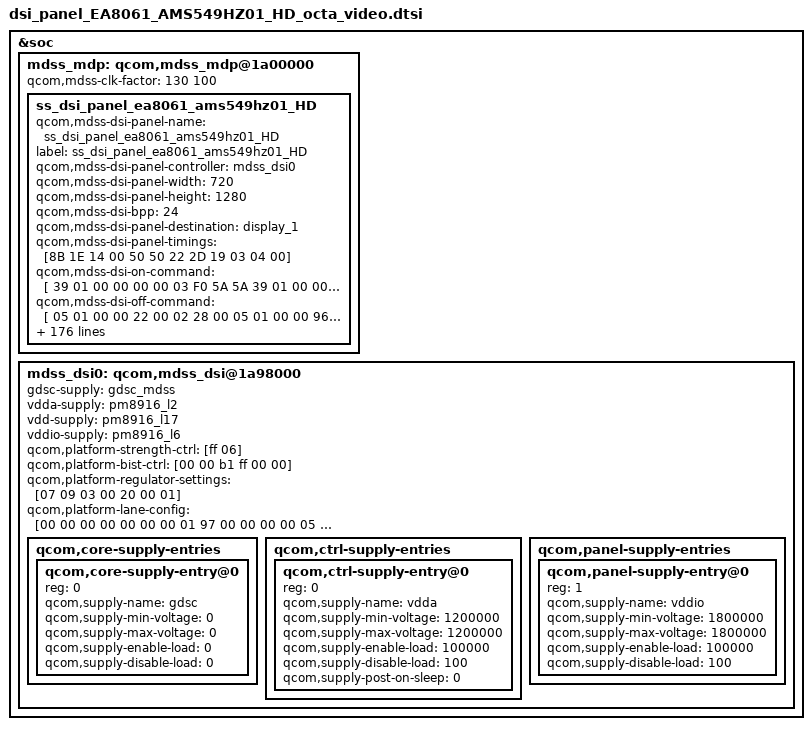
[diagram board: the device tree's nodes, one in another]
/* Copyright (c) 2013-2014, The Linux Foundation. All rights reserved.
 *
 * This program is free software; you can redistribute it and/or modify
 * it under the terms of the GNU General Public License version 2 and
 * only version 2 as published by the Free Software Foundation.
 *
 * This program is distributed in the hope that it will be useful,
 * but WITHOUT ANY WARRANTY; without even the implied warranty of
 * MERCHANTABILITY or FITNESS FOR A PARTICULAR PURPOSE.  See the
 * GNU General Public License for more details.
 */

/*---------------------------------------------------------------------------
 * This file is autogenerated file using gcdb parser. Please do not edit it.
 * Update input XML file to add a new entry or update variable in this file
 * VERSION = "1.0"
 *--------------------------------------------------------------------------- */
&mdss_mdp {
	ss_dsi_panel_ea8061_ams549hz01_HD: ss_dsi_panel_ea8061_ams549hz01_HD {
		qcom,mdss-dsi-panel-name = "ss_dsi_panel_ea8061_ams549hz01_HD";
		label = "ss_dsi_panel_ea8061_ams549hz01_HD";
		qcom,mdss-dsi-panel-controller = <&mdss_dsi0>;

		qcom,mdss-dsi-panel-width = <720>;
		qcom,mdss-dsi-panel-height = <1280>;
		qcom,mdss-dsi-bpp = <24>;
		qcom,mdss-dsi-panel-destination = "display_1";

		//qcom,mdss-dsi-panel-timings = [8B 1E 14 00 44 48 18 22 19 03 04 00];	// 488Mbps
		//qcom,mdss-dsi-panel-timings = [8B 1E 14 00 44 46 18 20 19 03 04 00];  // 481 Mbps
		qcom,mdss-dsi-panel-timings = [8B 1E 14 00 50 50 22 2D 19 03 04 00]; // New

		qcom,mdss-dsi-on-command = [
			// 4. Common Setting
			39 01 00 00 00 00 03 F0 5A 5A
			39 01 00 00 01 00 03 F7 5A 5A
			39 01 00 00 01 00 20
			/* (481 Mbps) */
			C4 51 AD 51 AD 60 95 60
			95 00 00 0B F1 00 0B F1
			00 00 08 08 08 34 64 A5
			00 00 0A 04 03 00 0C 00

			39 01 00 00 01 00 03 F7 A5 A5
			39 01 00 00 01 00 02 36 02		// Scan Direction : Reverse Scan
			39 01 00 00 01 00 05 B3 00 00 00 30	// AOR 3.7 %
			39 01 00 00 01 00 04 B4 33 07 00	// SLEW Control

			05 01 00 00 78 00 02 11 00		// sleep out &  Wait 120 ms

			// 5. Brightness Setting
			39 01 00 00 01 00 03 F7 5A 5A
			39 01 00 00 01 00 21
			CA 01 00 01 00 01 00 80			// 350 nit / 2.0 Gamma
			80 80 80 80 80 80 80 80
			80 80 80 80 80 80 80 80
			80 80 80 80 80 80 80 00
			00
			39 01 00 00 01 00 05 B3 00 00 00 30		// AOR 3.7%
			39 01 00 00 01 00 03 F7 A5 A5
			39 01 00 00 01 00 07 B2 0F B4 A0 13 00 00	// ELVSS SET
			39 01 00 00 01 00 03 F1 5A 5A
			39 01 00 00 01 00 04 D4 38 00 48		// MPS SET
			39 01 00 00 01 00 03 F1 A5 A5
			39 01 00 00 01 00 02 55 02			// 0x00 : ACL2 OFF,  0x02 : ACL 15 %

			// 6. ELVSS Temp Compensation
			39 01 00 00 01 00 02 B0 06			// Global Para (7)
			39 01 00 00 01 00 02 B2 19			// 0x19 : 25 Celsius
			39 01 00 00 01 00 03 F1 5A 5A
			39 01 00 00 01 00 02 B0 02			// Global Para (3)
			39 01 00 00 01 00 02 D4 48			// MPS Temp Offset OFF
			39 01 00 00 01 00 03 F1 A5 A5
			39 01 00 00 01 00 02 B2 0F

			// 7. ETC Condition Setting
			// 7.1 Test1 OUT (DE)
			39 01 00 00 01 00 03  F1 5A 5A
			39 01 00 00 01 00 03  FC 5A 5A
			39 01 00 00 01 00 02  B0 01
			39 01 00 00 01 00 02  D7 0A
			39 01 00 00 01 00 02  FF 0A
			39 01 00 00 01 00 03  F1 A5 A5
			39 01 00 00 01 00 03  FC A5 A5

			05 01 00 00 22 00 02 29 00
		];

		qcom,mdss-dsi-off-command = [
			05 01 00 00 22 00 02 28 00
			05 01 00 00 96 00 02 10 00
		];

		qcom,cont-splash-enabled;
		qcom,mdss-dsi-h-back-porch = <128>;
		qcom,mdss-dsi-h-front-porch = <84>;
		qcom,mdss-dsi-h-pulse-width = <96>;
		qcom,mdss-dsi-h-sync-skew = <0>;
		qcom,mdss-dsi-v-back-porch = <5>;
		qcom,mdss-dsi-v-front-porch = <13>;
		qcom,mdss-dsi-v-pulse-width = <2>;

		qcom,mdss-dsi-h-left-border = <0>;
		qcom,mdss-dsi-h-right-border = <0>;
		qcom,mdss-dsi-v-top-border = <0>;
		qcom,mdss-dsi-v-bottom-border = <0>;

		qcom,mdss-dsi-underflow-color = <0xff>;
		qcom,mdss-dsi-border-color = <0>;

		/* Dynamic FPS */
		/* qcom,mdss-dsi-pan-enable-dynamic-fps= <1>; */
		/* qcom,mdss-dsi-pan-fps-update = "dfps_immediate_porch_mode"; */

		qcom,mdss-dsi-bl-pmic-control-type = "bl_ctrl_dcs";
		qcom,mdss-dsi-bl-min-level = <1>;
		qcom,mdss-dsi-bl-max-level = <255>;
		qcom,mdss-brightness-max-level = <255>;
		qcom,mdss-dsi-panel-type = "dsi_video_mode";

		qcom,mdss-dsi-gamma-update = [
			39 01 00 00 00 00 02 F7 01
		];
		qcom,mdss-dsi-h-sync-pulse = <0>;
		qcom,mdss-dsi-bllp-eof-power-mode;
		qcom,mdss-dsi-bllp-power-mode;
		qcom,mdss-dsi-traffic-mode = "burst_mode";
		qcom,mdss-dsi-virtual-channel-id = <0>;
		qcom,mdss-dsi-lane-0-state;
		qcom,mdss-dsi-lane-1-state;
		qcom,mdss-dsi-lane-2-state;
		qcom,mdss-dsi-lane-3-state;

		qcom,mdss-dsi-t-clk-pre = <0x1C>;
		qcom,mdss-dsi-t-clk-post = <0x04>;

		qcom,mdss-dsi-stream = <0>;
		qcom,mdss-dsi-mdp-trigger = "none";
		qcom,mdss-dsi-dma-trigger = "trigger_sw";
		qcom,mdss-dsi-panel-framerate = <60>;
		qcom,mdss-dsi-on-command-state = "dsi_lp_mode";
		qcom,mdss-dsi-off-command-state = "dsi_hs_mode";
		qcom,mdss-pan-physical-width-dimension = <68>;
		qcom,mdss-pan-physical-height-dimension = <121>;
		qcom,mdss-dsi-force-clk-lane-hs = <1>;
		qcom,mdss-dsi-reset-sequence = <1 20>, <0 1>, <1 20>;

		qcom,mdss-dsi-lp11-init;
		qcom,mdss-dsi-init-delay-us = <2000>;
		qcom,mdss-power-off-delay-us = <12000>;
		samsung,mdss-power-on-reset-delay-us = <3000>;
		/*qcom,ulps-enabled*/
/*
 * ************************************************************************************************************************************
 *
 *			Below  parameters are samsung dependent thigs
 *
 * ************************************************************************************************************************************
 */
		/*samsung,dsi-lp11-init;  */
		samsung,packet_size_tx_cmds_revA = [
			37 01 00 00 00 00 02 07 00
		];

		samsung,reg_read_pos_tx_cmds_revA = [
			15 01 00 00 00 00 02 B0 00
		];
		samsung,display_on_tx_cmds_revA = [05 01 00 00 32 00 02 29 00];
		samsung,display_off_tx_cmds_revA = [05 01 00 00 32 00 02 28 00];

		samsung,level1_key_enable_tx_cmds_revA  = [39 00 00 00 00 00 03 F0 5A 5A];
		samsung,level1_key_disable_tx_cmds_revA = [39 00 00 00 00 00 03 F0 A5 A5];
		samsung,level2_key_enable_tx_cmds_revA = [
						39 00 00 00 00 00 03 F0 5A 5A
						39 00 00 00 00 00 03 F1 5A 5A
						39 01 00 00 00 00 03 FC 5A 5A
		];
		samsung,level2_key_disable_tx_cmds_revA = [
						39 00 00 00 00 00 03 F0 5A 5A
						39 00 00 00 00 00 03 F1 A5 A5
						39 01 00 00 00 00 03 FC A5 A5
		];

		samsung,manufacture_read_pre_tx_cmds_revA = [
						05 01 00 00 78 00 02 11 00		// sleep out
						39 01 00 00 00 00 03 FD DA 00		// mtp read
						];

		/*
		 * ************************************************************************************************************************
		 *	 06 01 00 00 00 00 01 c8 07 21
		 *	READ 0xC8 SIZE 0x07 OFFSET 0x21
		 * ************************************************************************************************************************
		 */
		samsung,panel-mtp-read-cmds = [ 39 01 00 00 00 00 03 FD DA 00];

		//=================================
		// REV. A
		//=================================
		samsung,smart_dimming_mtp_rx_cmds_revA = [ 06 01 00 00 00 00 01 FE 20 00];
		samsung,manufacture_id0_rx_cmds_revA   = [ 06 01 00 00 00 00 01 DA 01 00];
		samsung,manufacture_id1_rx_cmds_revA   = [ 06 01 00 00 00 00 01 DB 01 00];
		samsung,manufacture_id2_rx_cmds_revA   = [ 06 01 00 00 00 00 01 DC 01 00];
		samsung,manufacture_date_rx_cmds_revA  = [ 06 01 00 00 00 00 01 FE 02 32];	// read B6 24~25th, 23=0x17
		samsung,ddi_id_rx_cmds_revA            = [ 06 01 00 00 00 00 01 d6 05 00];	// read D6 1~5th
		samsung,mtp_read_sysfs_rx_cmds_revA    = [ 06 01 00 00 00 00 01 01 01 01];
		samsung,elvss_rx_cmds_revA             = [ 06 01 00 00 00 00 01 FE 01 11];	// read C6 21th, 20=0x14
		samsung,ldi_debug0_rx_cmds_revA        = [ 06 01 00 00 00 00 01 0A 01 00];
		samsung,ldi_debug1_rx_cmds_revA        = [ 06 01 00 00 00 00 01 0E 01 00];
		samsung,ldi_debug2_rx_cmds_revA        = [ 06 01 00 00 00 00 01 EA 08 00];
		samsung,hbm_rx_cmds_revA               = [ 06 01 00 00 00 00 01 FE 15 00];	// read DB 1~21th, 00=0x00
		samsung,hbm2_rx_cmds_revA              = [ 06 01 00 00 00 00 01 FE 01 21];	// read DB 34th, 33=0x21

		//=================================
		// REV. E
		//=================================
		samsung,smart_dimming_mtp_rx_cmds_revE = [ 06 01 00 00 00 00 01 FE 20 00];
		samsung,manufacture_id0_rx_cmds_revE   = [ 06 01 00 00 00 00 01 DA 01 00];
		samsung,manufacture_id1_rx_cmds_revE   = [ 06 01 00 00 00 00 01 DB 01 00];
		samsung,manufacture_id2_rx_cmds_revE   = [ 06 01 00 00 00 00 01 DC 01 00];
		samsung,manufacture_date_rx_cmds_revE  = [ 06 01 00 00 00 00 01 FE 02 32];	// read B6 24~25th, 23=0x17
		samsung,ddi_id_rx_cmds_revE            = [ 06 01 00 00 00 00 01 d6 02 32];	// read D6 1~5th
		samsung,mtp_read_sysfs_rx_cmds_revE    = [ 06 01 00 00 00 00 01 01 01 01];
		samsung,elvss_rx_cmds_revE             = [ 06 01 00 00 00 00 01 FE 01 11];	// read C6 21th, 20=0x14
		samsung,ldi_debug0_rx_cmds_revE        = [ 06 01 00 00 00 00 01 0A 01 00];
		samsung,ldi_debug1_rx_cmds_revE        = [ 06 01 00 00 00 00 01 0E 01 00];
		samsung,ldi_debug2_rx_cmds_revE        = [ 06 01 00 00 00 00 01 EA 08 00];
		samsung,hbm_rx_cmds_revE               = [ 06 01 00 00 00 00 01 FE 15 00];	// read DB 1~21th, 00=0x00
		samsung,hbm2_rx_cmds_revE              = [ 06 01 00 00 00 00 01 FE 01 21];	// read DB 34th, 33=0x21

		/*
		 * ************************************************************************************************************************
		 *	 COMMON CMD LIST
		 * ************************************************************************************************************************
		 */
		samsung,elvss_lowtemp_tx_cmds_revA  = [	29 01 00 00 00 00 02 B2 00 ];	/* Low Temperature Command */
		samsung,elvss_lowtemp2_tx_cmds_revA = [	29 01 00 00 00 00 02 B2 00 ];	/* Low Temperature Command: default */

		//========================================
		// Gamma and HBM (REV. A)
		//========================================
		samsung,gamma_tx_cmds_revA = [
			39 01 00 00 00 00 02 B0 06
			39 01 00 00 00 00 02 B2 25
			39 01 00 00 00 00 02 B0 02
			39 01 00 00 00 00 02 D4 48
			39 01 00 00 00 00 03 F7 5A 5A
			39 01 00 00 00 00 21 CA 01
			00 01 00 01 00 80 80 80
			80 80 80 80 80 80 80 80
			80 80 80 80 80 80 80 80
			80 80 80 80 80 00 00
			39 01 00 00 00 00 03 F7 A5 A5
		];

		samsung,hbm_gamma_tx_cmds_revA = [
			39 01 00 00 00 00 03 F7 5A 5A
			39 01 00 00 00 00 21 CA 01
			00 01 00 01 00 80 80 80
			80 80 80 80 80 80 80 80
			80 80 80 80 80 80 80 80
			80 80 80 80 80 00 00
			39 01 00 00 00 00 03 F7 A5 A5
		];

		samsung,hbm_etc_tx_cmds_revA = [
			39 00 00 00 00 00 05 B3 00 06 00 06
			39 00 00 00 00 00 08 B2 0F B4 A0 13 00 00 00
			39 00 00 00 00 00 04 B4 35 0A 00
			39 00 00 00 00 00 1F D4 38 00 48
			00 00 00 00 00 00 00
			00 00 00 60 66 C6 0C
			00 00 00 00 00 00 00
			00 00 00 00 00 00
			39 00 00 00 00 00 02 55 02
		];

		//========================================
		// Gamma and HBM (REV. E)
		//========================================
		samsung,gamma_tx_cmds_revE = [
			39 01 00 00 00 00 02 B0 06
			39 01 00 00 00 00 02 B2 19                      // TSET : 0x19 : 25 Celsius
			39 00 00 00 00 00 03 F1 5A 5A
			39 01 00 00 00 00 02 B0 02                      // Global Para 3rd
			39 01 00 00 00 00 02 D4 48                      // MPS Setting : MPS Temp offset off
			39 01 00 00 00 00 02 B0 11                      // Global Para 18 th
			39 01 00 00 00 00 02 D4 0C                      /* elvss set */
			39 00 00 00 00 00 03 F1 A5 A5
			39 01 00 00 00 00 03 F7 5A 5A                   /* Gamma, LTPS(AID) update */
			39 01 00 00 00 00 21 CA 01                      /* Brightness Condition Set - Gamma 2.0 Setting*/
			00 01 00 01 00 80 80 80
			80 80 80 80 80 80 80 80
			80 80 80 80 80 80 80 80
			80 80 80 80 80 00 00
			39 01 00 00 00 00 03 F7 A5 A5                   /* Gamma, LTPS(AID) update */
		];

		samsung,hbm_gamma_tx_cmds_revE = [
			39 01 00 00 00 00 03 F7 5A 5A
			39 01 00 00 00 00 21 CA 01			/* Brightness Condition Set - Gamma 2.0 Setting*/
			00 01 00 01 00 80 80 80
			80 80 80 80 80 80 80 80
			80 80 80 80 80 80 80 80
			80 80 80 80 80 00 00
			39 01 00 00 00 00 03 F7 A5 A5
		];

		samsung,hbm_etc_tx_cmds_revE = [
			39 00 00 00 00 00 05 B3 00 00 00 30             // AOR 3.7 %
			39 00 00 00 00 00 07 B2 0F B4 A0 13 00 00       // ELVSS SET
			39 00 00 00 00 00 03 F1 5A 5A
			39 00 00 00 00 00 1F D4 38 00 48
			00 00 00 00 00 00 00
			00 00 00 60 66 C6 0C
			00 00 00 00 00 00 00                            // DB 34th Para
			00 00 00 00 00 00
			39 00 00 00 00 00 03 F1 A5 A5
			39 00 00 00 00 00 02 55 02                      //0x02 :  ACL 15 %
		];

		//========================================
		// AID command list and mappings (REV. A)
		//========================================
		samsung,aid_tx_cmds_revA = [
			39 01 00 00 00 00 05	B3 00 00 04 EB	/* 0 samsung_brightness_aor_96p37 */
			39 01 00 00 00 00 05	B3 00 00 04 DE	/* 1 samsung_brightness_aor_95p29 */
			39 01 00 00 00 00 05	B3 00 00 04 D6	/* 2 samsung_brightness_aor_94p29 */
			39 01 00 00 00 00 05	B3 00 00 04 CB	/* 3 samsung_brightness_aor_93p75 */
			39 01 00 00 00 00 05	B3 00 00 04 BE	/* 4 samsung_brightness_aor_92p82 */
			39 01 00 00 00 00 05	B3 00 00 04 B7	/* 5 samsung_brightness_aor_91p82 */
			39 01 00 00 00 00 05	B3 00 00 04 AC	/* 6 samsung_brightness_aor_90p74 */
			39 01 00 00 00 00 05	B3 00 00 04 9F	/* 7 samsung_brightness_aor_90p28 */
			39 01 00 00 00 00 05	B3 00 00 04 98	/* 8 samsung_brightness_aor_89p20 */
			39 01 00 00 00 00 05	B3 00 00 04 8C	/* 9 samsung_brightness_aor_88p12 */
			39 01 00 00 00 00 05	B3 00 00 04 88	/* 10 samsung_brightness_aor_87p11 */
			39 01 00 00 00 00 05	B3 00 00 04 78	/* 11 samsung_brightness_aor_86p57 */
			39 01 00 00 00 00 05	B3 00 00 04 6D	/* 12 samsung_brightness_aor_85p57 */
			39 01 00 00 00 00 05	B3 00 00 04 57	/* 13 samsung_brightness_aor_83p41 */
			39 01 00 00 00 00 05	B3 00 00 04 4C	/* 14 samsung_brightness_aor_82p87 */
			39 01 00 00 00 00 05	B3 00 00 04 3D	/* 15 samsung_brightness_aor_81p87 */
			39 01 00 00 00 00 05	B3 00 00 04 30	/* 16 samsung_brightness_aor_81p40 */
			39 01 00 00 00 00 05	B3 00 00 04 1B	/* 17 samsung_brightness_aor_79p32 */
			39 01 00 00 00 00 05	B3 00 00 04 0C	/* 18 samsung_brightness_aor_78p24 */
			39 01 00 00 00 00 05	B3 00 00 03 F2	/* 19 samsung_brightness_aor_76p24 */
			39 01 00 00 00 00 05	B3 00 00 03 D9	/* 20 samsung_brightness_aor_74p69 */
			39 01 00 00 00 00 05	B3 00 00 03 D0	/* 21 samsung_brightness_aor_74p23 */
			39 01 00 00 00 00 05	B3 00 00 03 B8	/* 22 samsung_brightness_aor_72p07 */
			39 01 00 00 00 00 05	B3 00 00 03 A0	/* 23 samsung_brightness_aor_70p68 */
			39 01 00 00 00 00 05	B3 00 00 03 80	/* 24 samsung_brightness_aor_68p06 */
			39 01 00 00 00 00 05	B3 00 00 03 69	/* 25 samsung_brightness_aor_65p74 */
			39 01 00 00 00 00 05	B3 00 00 03 51	/* 26 samsung_brightness_aor_64p35 */
			39 01 00 00 00 00 05	B3 00 00 03 2E	/* 27 samsung_brightness_aor_61p11 */
			39 01 00 00 00 00 05	B3 00 00 03 0C	/* 28 samsung_brightness_aor_58p49 */
			39 01 00 00 00 00 05	B3 00 00 02 E9	/* 29 samsung_brightness_aor_55p71 */
			39 01 00 00 00 00 05	B3 00 00 02 C5	/* 30 samsung_brightness_aor_52p47 */
			39 01 00 00 00 00 05	B3 00 00 02 A1	/* 31 samsung_brightness_aor_49p69 */
			39 01 00 00 00 00 05	B3 00 00 02 70	/* 32 samsung_brightness_aor_45p99 */
			39 01 00 00 00 00 05	B3 00 00 02 41	/* 33 samsung_brightness_aor_42p52 */
			39 01 00 00 00 00 05	B3 00 00 02 10	/* 34 samsung_brightness_aor_39p89 */
			39 01 00 00 00 00 05	B3 00 00 01 DC	/* 35 samsung_brightness_aor_39p89 */
			39 01 00 00 00 00 05	B3 00 00 01 DC	/* 36 samsung_brightness_aor_33p95 */
			39 01 00 00 00 00 05	B3 00 00 01 A0	/* 37 samsung_brightness_aor_29p78 */
			39 01 00 00 00 00 05	B3 00 00 01 60	/* 38 samsung_brightness_aor_23p77 */
			39 01 00 00 00 00 05	B3 00 00 01 1C	/* 39 samsung_brightness_aor_18p83 */
			39 01 00 00 00 00 05	B3 00 00 00 D7	/* 40 samsung_brightness_aor_12p89 */
			39 01 00 00 00 00 05	B3 00 00 00 87	/* 41 samsung_brightness_aor_7p56 */
			39 01 00 00 00 00 05	B3 00 00 00 30	/* 42 samsung_brightness_aor_0p46 */
		];

		samsung,aid_map_table_revA = <
			5	0		6	1		7	2		8	3		9	4
			10	5		11	6		12	7		13	8		14	9
			15	10		16	11		17	12		19	13		20	14
			21	15		22	16		24	17		25	18		27	19	// 20
			29	20		30	21		32	22		34	23		37	24
			39	25		41	26		44	27		47	28		50	29
			53	30		56	31		60	32		64	33		68	34
			72	35		77	35		82	35		87	35		93	35	// 40
			98	35		105	35		111	35		119	35		126	35
			134	35		143	35		152	35		162	35		172	36
			183	37		195	38		207	39		220	40		234	41
			249	42		265	42		282	42		300	42		316	42	// 60
			333	42		350	42
		>;

		//=======================================
		// AID command list and mappings (REV. E)
		//=======================================
		samsung,aid_tx_cmds_revE = [
			39 01 00 00 00 00 05	B3 00 00 04 EB	/* 0 samsung_brightness_aor_96p37 */
			39 01 00 00 00 00 05	B3 00 00 04 DE	/* 1 samsung_brightness_aor_95p29 */
			39 01 00 00 00 00 05	B3 00 00 04 D6	/* 2 samsung_brightness_aor_94p29 */
			39 01 00 00 00 00 05	B3 00 00 04 CB	/* 3 samsung_brightness_aor_93p75 */
			39 01 00 00 00 00 05	B3 00 00 04 BE	/* 4 samsung_brightness_aor_92p82 */
			39 01 00 00 00 00 05	B3 00 00 04 B7	/* 5 samsung_brightness_aor_91p82 */
			39 01 00 00 00 00 05	B3 00 00 04 AC	/* 6 samsung_brightness_aor_90p74 */
			39 01 00 00 00 00 05	B3 00 00 04 9F	/* 7 samsung_brightness_aor_90p28 */
			39 01 00 00 00 00 05	B3 00 00 04 98	/* 8 samsung_brightness_aor_89p20 */
			39 01 00 00 00 00 05	B3 00 00 04 8C	/* 9 samsung_brightness_aor_88p12 */
			39 01 00 00 00 00 05	B3 00 00 04 88	/* 10 samsung_brightness_aor_87p11 */
			39 01 00 00 00 00 05	B3 00 00 04 78	/* 11 samsung_brightness_aor_86p57 */
			39 01 00 00 00 00 05	B3 00 00 04 6D	/* 12 samsung_brightness_aor_85p57 */
			39 01 00 00 00 00 05	B3 00 00 04 57	/* 13 samsung_brightness_aor_83p41 */
			39 01 00 00 00 00 05	B3 00 00 04 4C	/* 14 samsung_brightness_aor_82p87 */
			39 01 00 00 00 00 05	B3 00 00 04 3D	/* 15 samsung_brightness_aor_81p87 */
			39 01 00 00 00 00 05	B3 00 00 04 30	/* 16 samsung_brightness_aor_81p40 */
			39 01 00 00 00 00 05	B3 00 00 04 1B	/* 17 samsung_brightness_aor_79p32 */
			39 01 00 00 00 00 05	B3 00 00 04 0C	/* 18 samsung_brightness_aor_78p24 */
			39 01 00 00 00 00 05	B3 00 00 03 F2	/* 19 samsung_brightness_aor_76p24 */
			39 01 00 00 00 00 05	B3 00 00 03 D9	/* 20 samsung_brightness_aor_74p69 */
			39 01 00 00 00 00 05	B3 00 00 03 D0	/* 21 samsung_brightness_aor_74p23 */
			39 01 00 00 00 00 05	B3 00 00 03 B8	/* 22 samsung_brightness_aor_72p07 */
			39 01 00 00 00 00 05	B3 00 00 03 A0	/* 23 samsung_brightness_aor_70p68 */
			39 01 00 00 00 00 05	B3 00 00 03 80	/* 24 samsung_brightness_aor_68p06 */
			39 01 00 00 00 00 05	B3 00 00 03 69	/* 25 samsung_brightness_aor_65p74 */
			39 01 00 00 00 00 05	B3 00 00 03 51	/* 26 samsung_brightness_aor_64p35 */
			39 01 00 00 00 00 05	B3 00 00 03 2E	/* 27 samsung_brightness_aor_61p11 */
			39 01 00 00 00 00 05	B3 00 00 03 0C	/* 28 samsung_brightness_aor_58p49 */
			39 01 00 00 00 00 05	B3 00 00 02 E9	/* 29 samsung_brightness_aor_55p71 */
			39 01 00 00 00 00 05	B3 00 00 02 C5	/* 30 samsung_brightness_aor_52p47 */
			39 01 00 00 00 00 05	B3 00 00 02 A1	/* 31 samsung_brightness_aor_49p69 */
			39 01 00 00 00 00 05	B3 00 00 02 70	/* 32 samsung_brightness_aor_45p99 */
			39 01 00 00 00 00 05	B3 00 00 02 41	/* 33 samsung_brightness_aor_42p52 */
			39 01 00 00 00 00 05	B3 00 00 02 10	/* 34 samsung_brightness_aor_39p89 */
			39 01 00 00 00 00 05	B3 00 00 01 DC	/* 35 samsung_brightness_aor_39p89 */
			39 01 00 00 00 00 05	B3 00 00 01 DC	/* 36 samsung_brightness_aor_33p95 */
			39 01 00 00 00 00 05	B3 00 00 01 A0	/* 37 samsung_brightness_aor_29p78 */
			39 01 00 00 00 00 05	B3 00 00 01 60	/* 38 samsung_brightness_aor_23p77 */
			39 01 00 00 00 00 05	B3 00 00 01 1C	/* 39 samsung_brightness_aor_18p83 */
			39 01 00 00 00 00 05	B3 00 00 00 D7	/* 40 samsung_brightness_aor_12p89 */
			39 01 00 00 00 00 05	B3 00 00 00 87	/* 41 samsung_brightness_aor_7p56 */
			39 01 00 00 00 00 05	B3 00 00 00 30	/* 42 samsung_brightness_aor_0p46 */
		];

		samsung,aid_map_table_revE = <
			5	0		6	1		7	2		8	3		9	4
			10	5		11	6		12	7		13	8		14	9
			15	10		16	11		17	12		19	13		20	14
			21	15		22	16		24	17		25	18		27	19
			29	20		30	21		32	22		34	23		37	24
			39	25		41	26		44	27		47	28		50	29
			53	30		56	31		60	32		64	33		68	34
			72	35		77	35		82	35		87	35		93	35
			98	35		105	35		111	35		119	35		126	35
			134	35		143	35		152	35		162	35		172	36
			183	37		195	38		207	39		220	40		234	41
			249	42		265	42		282	42		300	42		316	42
			333	42		350	42
		>;

		//========================================
		// ACL command list and mappings (REV. A)
		//========================================
		samsung,samsung_change_acl_by_brightness;
		samsung,acl_on_tx_cmds_revA  = [ 39 01 00 00 00 00 02 55 02 ];
		samsung,acl_off_tx_cmds_revA = [ 39 01 00 00 72 00 02 55 00 ];

		samsung,acl_percent_tx_cmds_revA = [
			39 00 00 00 00 00 02 55 00	// 0x00 : ACL OFF
			39 00 00 00 00 00 02 55 01
			39 00 00 00 00 00 02 55 02	// 0x02 : ACL 15 %
			39 00 00 00 00 00 02 55 03
		];

		samsung,acl_map_table_revA =  <
			5    2	6    2	7    2	8    2	9    2
			10   2	11   2	12   2	13   2	14   2
			15   2	16   2	17   2	19   2	20   2
			21   2	22   2	24   2	25   2	27   2
			29   2	30   2	32   2	34   2	37   2
			39   2	41   2	44   2	47   2	50   2
			53   2	56   2	60   2	64   2	68   2
			72   2	77   2	82   2	87   2	93   2
			98   2	105  2	111  2	119  2	126  2
			134  2	143  2	152  2	162  2	172  2
			183  2	195  2	207  2	220  2	234  2
			249  2	265  2	282  2	300  2	316  2
			333  2	350  2
		>;

		//======================================
		// ACL command list and mappings (REV.E)
		//======================================
		samsung,acl_on_tx_cmds_revE  = [ 39 01 00 00 00 00 02 55 02 ];
		samsung,acl_off_tx_cmds_revE = [ 39 01 00 00 72 00 02 55 00 ];

		samsung,acl_percent_tx_cmds_revE = [
			39 00 00 00 00 00 02 55 00 /* 0 */
			39 00 00 00 00 00 02 55 01 /* 1 */
			39 00 00 00 00 00 02 55 02 /* 2 */
			39 00 00 00 00 00 02 55 03 /* 3 */
		];

		samsung,acl_map_table_revE =  <
			5    2	6    2	7    2	8    2	9    2
			10   2	11   2	12   2	13   2	14   2
			15   2	16   2	17   2	19   2	20   2
			21   2	22   2	24   2	25   2	27   2
			29   2	30   2	32   2	34   2	37   2
			39   2	41   2	44   2	47   2	50   2
			53   2	56   2	60   2	64   2	68   2
			72   2	77   2	82   2	87   2	93   2
			98   2	105  2	111  2	119  2	126  2
			134  2	143  2	152  2	162  2	172  2
			183  2	195  2	207  2	220  2	234  2
			249  2	265  2	282  2	300  2	316  2
			333  2	350  2
		>;
		/*
		 * ************************************************************************************************************************
		 * ELVSS(ACL Off) command list and mappings
		 * ************************************************************************************************************************
		 */
		samsung,elvss_tx_cmds_revA = [
			39 01 00 00 00 00 02 b2 0F /* 0    5 nit */
			39 01 00 00 00 00 02 b2 0F /* 1    6 nit */
			39 01 00 00 00 00 02 b2 0F /* 2    7 nit */
			39 01 00 00 00 00 02 b2 0F /* 3    8 nit */
			39 01 00 00 00 00 02 b2 0F /* 4    9 nit */
			39 01 00 00 00 00 02 b2 0F /* 5    10 nit */
			39 01 00 00 00 00 02 b2 0F /* 6    11 nit */
			39 01 00 00 00 00 02 b2 0F /* 7    12 nit */
			39 01 00 00 00 00 02 b2 0F /* 8    13 nit */
			39 01 00 00 00 00 02 b2 0F /* 9    14 nit */
			39 01 00 00 00 00 02 b2 0F /* 10   15 nit */
			39 01 00 00 00 00 02 b2 0F /* 11   16 nit */
			39 01 00 00 00 00 02 b2 0F /* 12   17 nit */
			39 01 00 00 00 00 02 b2 0F /* 13   19 nit */
			39 01 00 00 00 00 02 b2 0F /* 14   20 nit */
			39 01 00 00 00 00 02 b2 0F /* 15   21 nit */
			39 01 00 00 00 00 02 b2 11 /* 16   22 nit */
			39 01 00 00 00 00 02 b2 15 /* 17   24 nit */
			39 01 00 00 00 00 02 b2 18 /* 18   25 nit */
			39 01 00 00 00 00 02 b2 1B /* 19   27 nit */
			39 01 00 00 00 00 02 b2 19 /* 20   29 nit */
			39 01 00 00 00 00 02 b2 1C /* 21   30 ~ 105 nit */
			39 01 00 00 00 00 02 b2 1C /* 22   111 nit */
			39 01 00 00 00 00 02 b2 1B /* 23   119 nit */
			39 01 00 00 00 00 02 b2 1B /* 24   126 nit */
			39 01 00 00 00 00 02 b2 1A /* 25   134 nit */
			39 01 00 00 00 00 02 b2 19 /* 26   143 nit */
			39 01 00 00 00 00 02 b2 18 /* 27   152 nit */
			39 01 00 00 00 00 02 b2 17 /* 28   162 nit */
			39 01 00 00 00 00 02 b2 17 /* 29   172 nit */
			39 01 00 00 00 00 02 b2 17 /* 30   183 nit */
			39 01 00 00 00 00 02 b2 16 /* 31   195 nit */
			39 01 00 00 00 00 02 b2 15 /* 32   207 nit */
			39 01 00 00 00 00 02 b2 15 /* 33   220 nit */
			39 01 00 00 00 00 02 b2 15 /* 34   234 nit */
			39 01 00 00 00 00 02 b2 14 /* 35   249 nit */
			39 01 00 00 00 00 02 b2 14 /* 36   265 nit */
			39 01 00 00 00 00 02 b2 13 /* 37   282 nit */
			39 01 00 00 00 00 02 b2 12 /* 38   300 nit */
			39 01 00 00 00 00 02 b2 11 /* 39   316 nit */
			39 01 00 00 00 00 02 b2 10 /* 40   333 nit */
			39 01 00 00 00 00 02 b2 0F /* 41   350 nit */
		];

		samsung,elvss_tx_cmds_revE = [
			39 01 00 00 00 00 02 b2 0F /* 0    5 nit */
			39 01 00 00 00 00 02 b2 0F /* 1    6 nit */
			39 01 00 00 00 00 02 b2 0F /* 2    7 nit */
			39 01 00 00 00 00 02 b2 0F /* 3    8 nit */
			39 01 00 00 00 00 02 b2 0F /* 4    9 nit */
			39 01 00 00 00 00 02 b2 0F /* 5    10 nit */
			39 01 00 00 00 00 02 b2 0F /* 6    11 nit */
			39 01 00 00 00 00 02 b2 0F /* 7    12 nit */
			39 01 00 00 00 00 02 b2 0F /* 8    13 nit */
			39 01 00 00 00 00 02 b2 0F /* 9    14 nit */
			39 01 00 00 00 00 02 b2 0F /* 10   15 nit */
			39 01 00 00 00 00 02 b2 0F /* 11   16 nit */
			39 01 00 00 00 00 02 b2 0F /* 12   17 nit */
			39 01 00 00 00 00 02 b2 0F /* 13   19 nit */
			39 01 00 00 00 00 02 b2 0F /* 14   20 nit */
			39 01 00 00 00 00 02 b2 0F /* 15   21 nit */
			39 01 00 00 00 00 02 b2 11 /* 16   22 nit */
			39 01 00 00 00 00 02 b2 15 /* 17   24 nit */
			39 01 00 00 00 00 02 b2 18 /* 18   25 nit */
			39 01 00 00 00 00 02 b2 1B /* 19   27 nit */
			39 01 00 00 00 00 02 b2 19 /* 20   29 nit */
			39 01 00 00 00 00 02 b2 1C /* 21   30 ~ 105 nit */
			39 01 00 00 00 00 02 b2 1C /* 22   111 nit */
			39 01 00 00 00 00 02 b2 1B /* 23   119 nit */
			39 01 00 00 00 00 02 b2 1B /* 24   126 nit */
			39 01 00 00 00 00 02 b2 1A /* 25   134 nit */
			39 01 00 00 00 00 02 b2 19 /* 26   143 nit */
			39 01 00 00 00 00 02 b2 18 /* 27   152 nit */
			39 01 00 00 00 00 02 b2 17 /* 28   162 nit */
			39 01 00 00 00 00 02 b2 17 /* 29   172 nit */
			39 01 00 00 00 00 02 b2 17 /* 30   183 nit */
			39 01 00 00 00 00 02 b2 16 /* 31   195 nit */
			39 01 00 00 00 00 02 b2 15 /* 32   207 nit */
			39 01 00 00 00 00 02 b2 15 /* 33   220 nit */
			39 01 00 00 00 00 02 b2 15 /* 34   234 nit */
			39 01 00 00 00 00 02 b2 14 /* 35   249 nit */
			39 01 00 00 00 00 02 b2 14 /* 36   265 nit */
			39 01 00 00 00 00 02 b2 13 /* 37   282 nit */
			39 01 00 00 00 00 02 b2 12 /* 38   300 nit */
			39 01 00 00 00 00 02 b2 11 /* 39   316 nit */
			39 01 00 00 00 00 02 b2 10 /* 40   333 nit */
			39 01 00 00 00 00 02 b2 0F /* 41   350 nit */
		];

		/*
		 * ************************************************************************************************************************
		 * SMART ACL(ACL On) ELVSS command list and mappings
		 * ************************************************************************************************************************
		 */

		samsung,smart_acl_elvss_tx_cmds_revA = [
			39 01 00 00 00 00 02 b2 0F /* 0    5 nit */
			39 01 00 00 00 00 02 b2 0F /* 1    6 nit */
			39 01 00 00 00 00 02 b2 0F /* 2    7 nit */
			39 01 00 00 00 00 02 b2 0F /* 3    8 nit */
			39 01 00 00 00 00 02 b2 0F /* 4    9 nit */
			39 01 00 00 00 00 02 b2 0F /* 5    10 nit */
			39 01 00 00 00 00 02 b2 0F /* 6    11 nit */
			39 01 00 00 00 00 02 b2 0F /* 7    12 nit */
			39 01 00 00 00 00 02 b2 0F /* 8    13 nit */
			39 01 00 00 00 00 02 b2 0F /* 9    14 nit */
			39 01 00 00 00 00 02 b2 0F /* 10   15 nit */
			39 01 00 00 00 00 02 b2 0F /* 11   16 nit */
			39 01 00 00 00 00 02 b2 0F /* 12   17 nit */
			39 01 00 00 00 00 02 b2 0F /* 13   19 nit */
			39 01 00 00 00 00 02 b2 0F /* 14   20 nit */
			39 01 00 00 00 00 02 b2 0F /* 15   21 nit */
			39 01 00 00 00 00 02 b2 11 /* 16   22 nit */
			39 01 00 00 00 00 02 b2 15 /* 17   24 nit */
			39 01 00 00 00 00 02 b2 18 /* 18   25 nit */
			39 01 00 00 00 00 02 b2 1B /* 19   27 nit */
			39 01 00 00 00 00 02 b2 19 /* 20   29 nit */
			39 01 00 00 00 00 02 b2 1C /* 21   30 ~ 105 nit */
			39 01 00 00 00 00 02 b2 1C /* 22   111 nit */
			39 01 00 00 00 00 02 b2 1B /* 23   119 nit */
			39 01 00 00 00 00 02 b2 1B /* 24   126 nit */
			39 01 00 00 00 00 02 b2 1A /* 25   134 nit */
			39 01 00 00 00 00 02 b2 19 /* 26   143 nit */
			39 01 00 00 00 00 02 b2 18 /* 27   152 nit */
			39 01 00 00 00 00 02 b2 17 /* 28   162 nit */
			39 01 00 00 00 00 02 b2 17 /* 29   172 nit */
			39 01 00 00 00 00 02 b2 17 /* 30   183 nit */
			39 01 00 00 00 00 02 b2 16 /* 31   195 nit */
			39 01 00 00 00 00 02 b2 15 /* 32   207 nit */
			39 01 00 00 00 00 02 b2 15 /* 33   220 nit */
			39 01 00 00 00 00 02 b2 15 /* 34   234 nit */
			39 01 00 00 00 00 02 b2 14 /* 35   249 nit */
			39 01 00 00 00 00 02 b2 14 /* 36   265 nit */
			39 01 00 00 00 00 02 b2 13 /* 37   282 nit */
			39 01 00 00 00 00 02 b2 12 /* 38   300 nit */
			39 01 00 00 00 00 02 b2 11 /* 39   316 nit */
			39 01 00 00 00 00 02 b2 10 /* 40   333 nit */
			39 01 00 00 00 00 02 b2 0F /* 41   350 nit */
		];
		samsung,smart_acl_elvss_tx_cmds_revE = [
			39 01 00 00 00 00 02 b2 0F /* 0    5 nit */
			39 01 00 00 00 00 02 b2 0F /* 1    6 nit */
			39 01 00 00 00 00 02 b2 0F /* 2    7 nit */
			39 01 00 00 00 00 02 b2 0F /* 3    8 nit */
			39 01 00 00 00 00 02 b2 0F /* 4    9 nit */
			39 01 00 00 00 00 02 b2 0F /* 5    10 nit */
			39 01 00 00 00 00 02 b2 0F /* 6    11 nit */
			39 01 00 00 00 00 02 b2 0F /* 7    12 nit */
			39 01 00 00 00 00 02 b2 0F /* 8    13 nit */
			39 01 00 00 00 00 02 b2 0F /* 9    14 nit */
			39 01 00 00 00 00 02 b2 0F /* 10   15 nit */
			39 01 00 00 00 00 02 b2 0F /* 11   16 nit */
			39 01 00 00 00 00 02 b2 0F /* 12   17 nit */
			39 01 00 00 00 00 02 b2 0F /* 13   19 nit */
			39 01 00 00 00 00 02 b2 0F /* 14   20 nit */
			39 01 00 00 00 00 02 b2 0F /* 15   21 nit */
			39 01 00 00 00 00 02 b2 11 /* 16   22 nit */
			39 01 00 00 00 00 02 b2 15 /* 17   24 nit */
			39 01 00 00 00 00 02 b2 18 /* 18   25 nit */
			39 01 00 00 00 00 02 b2 1B /* 19   27 nit */
			39 01 00 00 00 00 02 b2 19 /* 20   29 nit */
			39 01 00 00 00 00 02 b2 1C /* 21   30 ~ 105 nit */
			39 01 00 00 00 00 02 b2 1C /* 22   111 nit */
			39 01 00 00 00 00 02 b2 1B /* 23   119 nit */
			39 01 00 00 00 00 02 b2 1B /* 24   126 nit */
			39 01 00 00 00 00 02 b2 1A /* 25   134 nit */
			39 01 00 00 00 00 02 b2 19 /* 26   143 nit */
			39 01 00 00 00 00 02 b2 18 /* 27   152 nit */
			39 01 00 00 00 00 02 b2 17 /* 28   162 nit */
			39 01 00 00 00 00 02 b2 17 /* 29   172 nit */
			39 01 00 00 00 00 02 b2 17 /* 30   183 nit */
			39 01 00 00 00 00 02 b2 16 /* 31   195 nit */
			39 01 00 00 00 00 02 b2 15 /* 32   207 nit */
			39 01 00 00 00 00 02 b2 15 /* 33   220 nit */
			39 01 00 00 00 00 02 b2 15 /* 34   234 nit */
			39 01 00 00 00 00 02 b2 14 /* 35   249 nit */
			39 01 00 00 00 00 02 b2 14 /* 36   265 nit */
			39 01 00 00 00 00 02 b2 13 /* 37   282 nit */
			39 01 00 00 00 00 02 b2 12 /* 38   300 nit */
			39 01 00 00 00 00 02 b2 11 /* 39   316 nit */
			39 01 00 00 00 00 02 b2 10 /* 40   333 nit */
			39 01 00 00 00 00 02 b2 0F /* 41   350 nit */
		];
		/* bl_level, Index in elvss command list */
		samsung,smart_acl_elvss_map_table_revA = <
					5	0		6	1		7	2		8	3		9	4
					10	5		11	6		12	7		13	8		14	9
					15	10		16	11		17	12		19	13		20	14
					21	15		22	16		24	17		25	18		27	19
					29	20		30	21		32	21		34	21		37	21
					39	21		41	21		44	21		47	21		50	21
					53	21		56	21		60	21		64	21		68	21
					72	21		77	21		82	21		87	21		93	21
					98	21		105	21		111	22		119	23		126	24
					134	25		143	26		152	27		162	28		172	29
					183	30		195	31		207	32		220	33		234	34
					249	35		265	36		282	37		300	38		316	39
					333	40		350	41
		>;
		samsung,smart_acl_elvss_map_table_revE = <
					5	0		6	1		7	2		8	3		9	4
					10	5		11	6		12	7		13	8		14	9
					15	10		16	11		17	12		19	13		20	14
					21	15		22	16		24	17		25	18		27	19
					29	20		30	21		32	21		34	21		37	21
					39	21		41	21		44	21		47	21		50	21
					53	21		56	21		60	21		64	21		68	21
					72	21		77	21		82	21		87	21		93	21
					98	21		105	21		111	22		119	23		126	24
					134	25		143	26		152	27		162	28		172	29
					183	30		195	31		207	32		220	33		234	34
					249	35		265	36		282	37		300	38		316	39
					333	40		350	41
		>;
		/*
		* ************************************************************************************************************************
		* candela to index mappings
		* ************************************************************************************************************************
		*/
		samsung,candela_map_table_revA = <
		/*<idx>	  <from>  <till> <candella> */
				0		0		5		5
				1		6		6		6
				2		7		7		7
				3		8		8		8
				4		9		9		9
				5		10		10		10
				6		11		11		11
				7		12		12		12
				8		13		13		13
				9		14		14		14
				10		15		15		15
				11		16		16		16
				12		17		17		17
				13		18		18		19
				14		19		19		20
				15		20		20		21
				16		21		21		22
				17		22		22		24
				18		23		23		25
				19		24		24		27
				20		25		25		29
				21		26		26		30
				22		27		27		32
				23		28		28		34
				24		29		29		37
				25		30		30		39
				26		31		32		41
				27		33		34		44
				28		35		36		47
				29		37		38		50
				30		39		40		53
				31		41		43		56
				32		44		45		60
				33		46		48		64
				34		49		51		68
				35		52		55		72
				36		56		59		77
				37		60		63		82
				38		64		67		87
				39		68		71		93
				40		71		74		98
				41		75		79		105
				42		80		85		111
				43		86		91		119
				44		92		97		126
				45		97		103		134
				46		104		110		143
				47		111		117		152
				48		118		125		162
				49		126		133		172
				50		134		142		183
				51		143		151		195
				52		152		161		207
				53		162		171		220
				54		172		182		234
				55		183		194		249
				56		195		206		265
				57		207		218		282
				58		219		230		300
				59		231		242		316
				60		243		253		333
				61		254		255		350
		>;
		samsung,candela_map_table_revE = <
		/*<idx>	  <from>  <till> <candella> */
				0		0		5		5
				1		6		6		6
				2		7		7		7
				3		8		8		8
				4		9		9		9
				5		10		10		10
				6		11		11		11
				7		12		12		12
				8		13		13		13
				9		14		14		14
				10		15		15		15
				11		16		16		16
				12		17		17		17
				13		18		18		19
				14		19		19		20
				15		20		20		21
				16		21		21		22
				17		22		22		24
				18		23		23		25
				19		24		24		27
				20		25		25		29
				21		26		26		30
				22		27		27		32
				23		28		28		34
				24		29		29		37
				25		30		30		39
				26		31		32		41
				27		33		34		44
				28		35		36		47
				29		37		38		50
				30		39		40		53
				31		41		43		56
				32		44		45		60
				33		46		48		64
				34		49		51		68
				35		52		55		72
				36		56		59		77
				37		60		63		82
				38		64		67		87
				39		68		71		93
				40		71		74		98
				41		75		79		105
				42		80		85		111
				43		86		91		119
				44		92		97		126
				45		97		103		134
				46		104		110		143
				47		111		117		152
				48		118		125		162
				49		126		133		172
				50		134		142		183
				51		143		151		195
				52		152		161		207
				53		162		171		220
				54		172		182		234
				55		183		194		249
				56		195		206		265
				57		207		218		282
				58		219		230		300
				59		231		242		316
				60		243		253		333
				61		254		255		350
		>;
	};
};

&soc {
	mdss_mdp: qcom,mdss_mdp@1a00000 {
			qcom,mdss-clk-factor = <130 100>;	/* 1.3 times */
	};
};

&soc {
	mdss_dsi0: qcom,mdss_dsi@1a98000 {
		gdsc-supply = <&gdsc_mdss>;
		vdda-supply = <&pm8916_l2>;
		vdd-supply = <&pm8916_l17>;
		vddio-supply = <&pm8916_l6>;
		qcom,platform-strength-ctrl = [ff 06];
		qcom,platform-bist-ctrl = [00 00 b1 ff 00 00];
		qcom,platform-regulator-settings = [07 09 03 00 20 00 01];
		qcom,platform-lane-config = [00 00 00 00 00 00 00 01 97
			00 00 00 00 05 00 00 01 97
			00 00 00 00 0a 00 00 01 97
			00 00 00 00 0f 00 00 01 97
			00 c0 00 00 00 00 00 01 bb];
		qcom,core-supply-entries {
			#address-cells = <1>;
			#size-cells = <0>;
			qcom,core-supply-entry@0 {
				reg = <0>;
				qcom,supply-name = "gdsc";
				qcom,supply-min-voltage = <0>;
				qcom,supply-max-voltage = <0>;
				qcom,supply-enable-load = <0>;
				qcom,supply-disable-load = <0>;
			};
		};
		qcom,ctrl-supply-entries {
			#address-cells = <1>;
			#size-cells = <0>;
			qcom,ctrl-supply-entry@0 {
				reg = <0>;
				qcom,supply-name = "vdda";
				qcom,supply-min-voltage = <1200000>;
				qcom,supply-max-voltage = <1200000>;
				qcom,supply-enable-load = <100000>;
				qcom,supply-disable-load = <100>;
				qcom,supply-post-on-sleep = <0>;
			};
		};
		qcom,panel-supply-entries {
			#address-cells = <1>;
			#size-cells = <0>;
			qcom,panel-supply-entry@0 {
				reg = <1>;
				qcom,supply-name = "vddio";
				qcom,supply-min-voltage = <1800000>;
				qcom,supply-max-voltage = <1800000>;
				qcom,supply-enable-load = <100000>;
				qcom,supply-disable-load = <100>;
			};
		};
	};
};
